# N32H49X register map
Vendor: Nsingtech Ltd.; File version: 1.0
Registers are 32-bit, read-write, reset 0x0 unless marked. A register's access mark holds for its fields unless they carry their own. Offsets are from the block's base; [hi:lo] are bit positions; {n}, {i} and the like mark numbered series; 'fields as' and 'values as' point back to an identical list.

## WWDG — window watchdog
Base 0x40000400
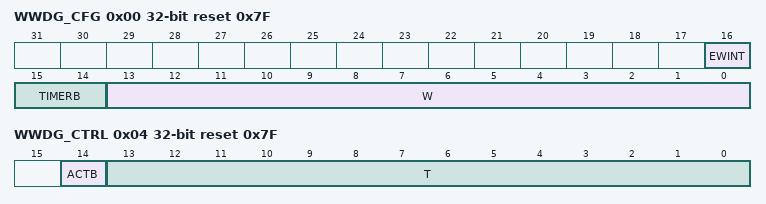
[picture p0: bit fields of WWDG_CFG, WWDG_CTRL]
0x00 WWDG_CFG reset 0x7F (reset mask 0x3FF)
  [16] EWINT, [15:14] TIMERB, [13:0] W
0x04 WWDG_CTRL reset 0x7F (reset mask 0xFF)
  [14] ACTB, [13:0] T
0x08 WWDG_STS
  [0] EWINTF

## DBG — debug support for MCU
Base 0xE0042000
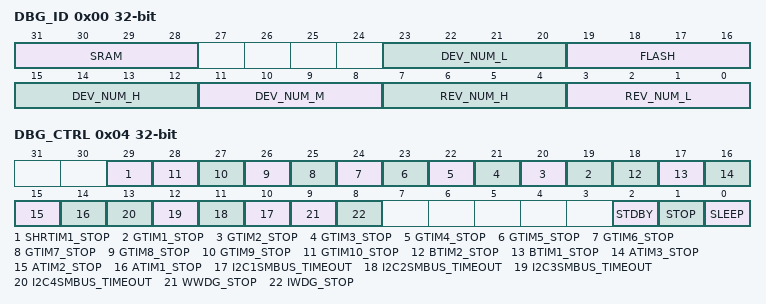
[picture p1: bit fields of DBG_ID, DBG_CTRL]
0x00 DBG_ID
  [31:28] SRAM, [23:20] DEV_NUM_L, [19:16] FLASH, [15:12] DEV_NUM_H, [11:8] DEV_NUM_M, [7:4] REV_NUM_H, [3:0] REV_NUM_L
0x04 DBG_CTRL (reset mask 0x3FFF07)
  [29] SHRTIM1_STOP, [n+18] GTIM{n}_STOP (n=1..10), [18] BTIM2_STOP, [17] BTIM1_STOP, [16] ATIM3_STOP, [15] ATIM2_STOP, [14] ATIM1_STOP, [n+9] I2C{n}SMBUS_TIMEOUT (n=1..4), [9] WWDG_STOP, [8] IWDG_STOP, [2] STDBY, [1] STOP, [0] SLEEP

## SPI1 — Serial peripheral interface
Base 0x40011800
Same registers: SPI2 0x40002400, SPI3 0x40002800, SPI4 0x40012C00, SPI5 0x40013000, SPI6 0x40013400
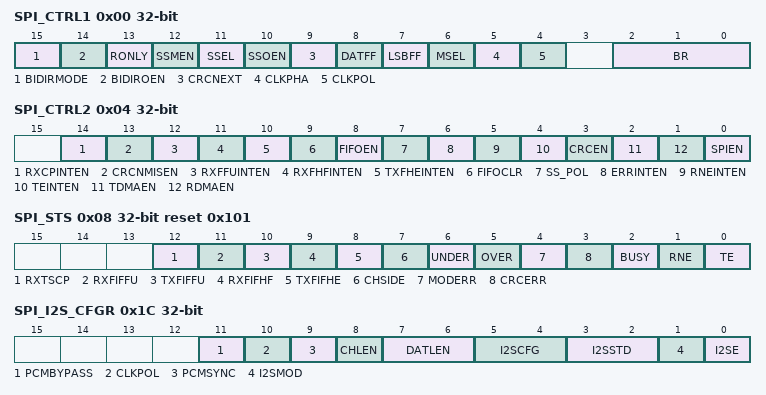
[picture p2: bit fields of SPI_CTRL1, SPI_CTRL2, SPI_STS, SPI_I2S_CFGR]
0x00 SPI_CTRL1
  [15] BIDIRMODE, [14] BIDIROEN, [13] RONLY, [12] SSMEN, [11] SSEL, [10] SSOEN, [9] CRCNEXT, [8] DATFF, [7] LSBFF, [6] MSEL, [5] CLKPHA, [4] CLKPOL, [2:0] BR
0x04 SPI_CTRL2
  [14] RXCPINTEN, [13] CRCNMISEN, [12] RXFFUINTEN, [11] RXFHFINTEN, [10] TXFHEINTEN, [9] FIFOCLR, [8] FIFOEN, [7] SS_POL, [6] ERRINTEN, [5] RNEINTEN, [4] TEINTEN, [3] CRCEN, [2] TDMAEN, [1] RDMAEN, [0] SPIEN
0x08 SPI_STS reset 0x101
  [12] RXTSCP, [11] RXFIFFU, [10] TXFIFFU, [9] RXFIFHF, [8] TXFIFHE, [7] CHSIDE, [6] UNDER, [5] OVER, [4] MODERR, [3] CRCERR, [2] BUSY, [1] RNE, [0] TE
0x0C SPI_DAT
  [15:0] DAT
0x10 SPI_CRCTDAT
  [15:0] CRCTDAT
0x14 SPI_CRCRDAT
  [15:0] CRCRDAT
0x18 SPI_CRCPOLY reset 0x7
  [15:0] CRCPOLY
0x1C SPI_I2S_CFGR
  [11] PCMBYPASS, [10] CLKPOL, [9] PCMSYNC, [8] CHLEN, [7:6] DATLEN, [5:4] I2SCFG, [3:2] I2SSTD, [1] I2SMOD, [0] I2SE
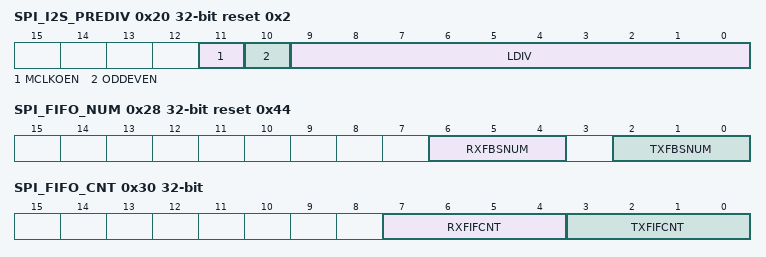
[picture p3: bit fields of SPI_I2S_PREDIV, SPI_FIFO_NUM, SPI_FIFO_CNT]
0x20 SPI_I2S_PREDIV reset 0x2
  [11] MCLKOEN, [10] ODDEVEN, [9:0] LDIV
0x24 SPI_RX_FIFO
  [15:0] RXFIFDAT
0x28 SPI_FIFO_NUM reset 0x44
  [6:4] RXFBSNUM, [2:0] TXFBSNUM
0x30 SPI_FIFO_CNT
  [7:4] RXFIFCNT, [3:0] TXFIFCNT
0x34 SPI_TRANS_NUM
  [15:0] TRANSNUM
0x38 SPI_CR3
  [3:0] DELAYTIME

## I2S2_EXT — Inter—IC Sound
Base 0x40002600
Same registers: I2S3_EXT 0x40002A00
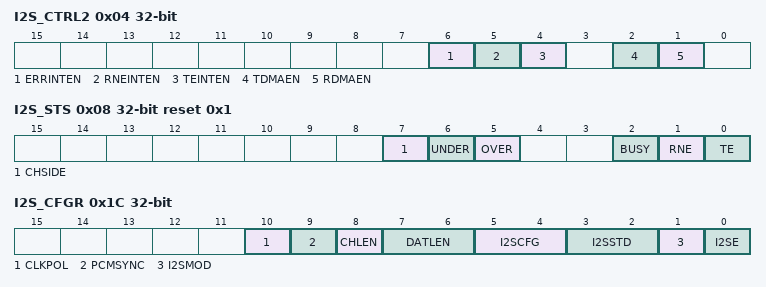
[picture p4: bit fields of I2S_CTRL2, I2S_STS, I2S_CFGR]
0x04 I2S_CTRL2
  [6] ERRINTEN, [5] RNEINTEN, [4] TEINTEN, [2] TDMAEN, [1] RDMAEN
0x08 I2S_STS reset 0x1
  [7] CHSIDE, [6] UNDER, [5] OVER, [2] BUSY, [1] RNE, [0] TE
0x0C I2S_DAT
  [15:0] DAT
0x1C I2S_CFGR
  [10] CLKPOL, [9] PCMSYNC, [8] CHLEN, [7:6] DATLEN, [5:4] I2SCFG, [3:2] I2SSTD, [1] I2SMOD, [0] I2SE

## DMA1 — Direct memory access controller
Base 0x40020000
Same registers: DMA2 0x40020400
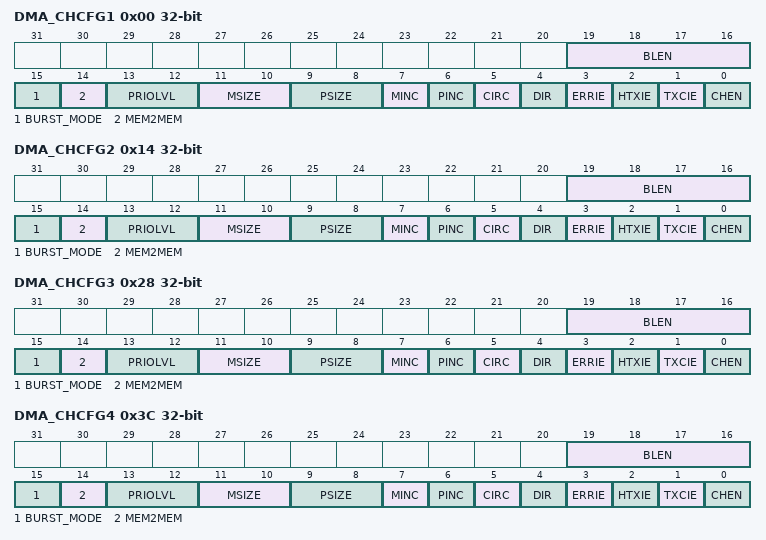
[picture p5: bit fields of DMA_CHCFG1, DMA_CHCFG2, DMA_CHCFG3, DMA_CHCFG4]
0x00 DMA_CHCFG1
  [19:16] BLEN, [15] BURST_MODE, [14] MEM2MEM, [13:12] PRIOLVL, [11:10] MSIZE, [9:8] PSIZE, [7] MINC, [6] PINC, [5] CIRC, [4] DIR, [3] ERRIE, [2] HTXIE, [1] TXCIE, [0] CHEN
0x04 DMA_MADDR1
  [31:0] ADDR
0x08 DMA_PADDR1
  [31:0] ADDR
0x0C DMA_CHSEL1
  [7:0] CH_SEL
0x10 DMA_TXNUM1
  [15:0] NDTX
0x14 DMA_CHCFG2
  fields as DMA_CHCFG1
0x18 DMA_MADDR2
  [31:0] ADDR
0x1C DMA_PADDR2
  [31:0] ADDR
0x20 DMA_CHSEL2
  [7:0] CH_SEL
0x24 DMA_TXNUM2
  [15:0] NDTX
0x28 DMA_CHCFG3
  fields as DMA_CHCFG1
0x2C DMA_MADDR3
  [31:0] ADDR
0x30 DMA_PADDR3
  [31:0] ADDR
0x34 DMA_CHSEL3
  [7:0] CH_SEL
0x38 DMA_TXNUM3
  [15:0] NDTX
0x3C DMA_CHCFG4
  fields as DMA_CHCFG1
0x40 DMA_MADDR4
  [31:0] ADDR
0x44 DMA_PADDR4
  [31:0] ADDR
0x48 DMA_CHSEL4
  [7:0] CH_SEL
0x4C DMA_TXNUM4
  [15:0] NDTX
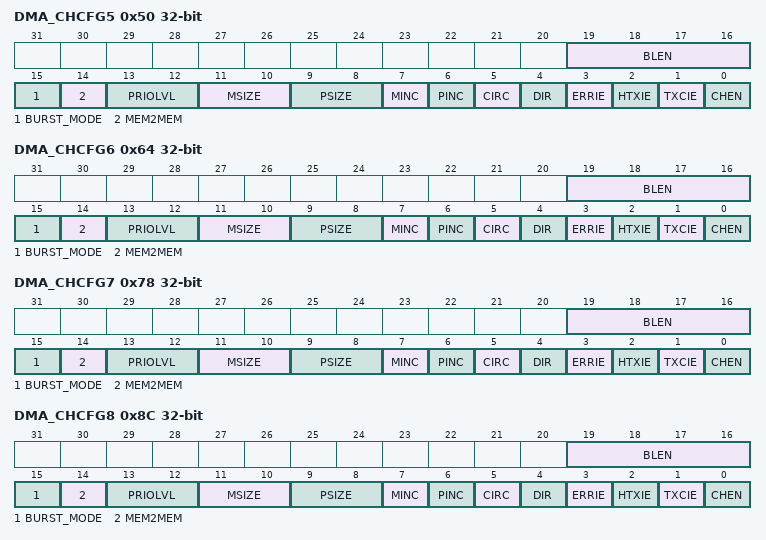
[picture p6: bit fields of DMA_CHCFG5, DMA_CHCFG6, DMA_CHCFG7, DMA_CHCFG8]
0x50 DMA_CHCFG5
  fields as DMA_CHCFG1
0x54 DMA_MADDR5
  [31:0] ADDR
0x58 DMA_PADDR5
  [31:0] ADDR
0x5C DMA_CHSEL5
  [7:0] CH_SEL
0x60 DMA_TXNUM5
  [15:0] NDTX
0x64 DMA_CHCFG6
  fields as DMA_CHCFG1
0x68 DMA_MADDR6
  [31:0] ADDR
0x6C DMA_PADDR6
  [31:0] ADDR
0x70 DMA_CHSEL6
  [7:0] CH_SEL
0x74 DMA_TXNUM6
  [15:0] NDTX
0x78 DMA_CHCFG7
  fields as DMA_CHCFG1
0x7C DMA_MADDR7
  [31:0] ADDR
0x80 DMA_PADDR7
  [31:0] ADDR
0x84 DMA_CHSEL7
  [7:0] CH_SEL
0x88 DMA_TXNUM7
  [15:0] NDTX
0x8C DMA_CHCFG8
  fields as DMA_CHCFG1
0x90 DMA_MADDR8
  [31:0] ADDR
0x94 DMA_PADDR8
  [31:0] ADDR
0x98 DMA_CHSEL8
  [7:0] CH_SEL
0x9C DMA_TXNUM8
  [15:0] NDTX
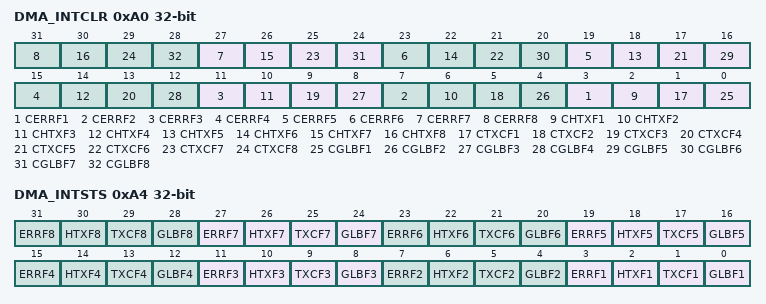
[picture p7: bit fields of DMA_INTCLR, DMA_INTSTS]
0xA0 DMA_INTCLR
  [4n-1] CERRF{n} (n=1..8), [4n-2] CHTXF{n} (n=1..8), [4n-3] CTXCF{n} (n=1..8), [4n-4] CGLBF{n} (n=1..8)
0xA4 DMA_INTSTS ro
  [4n-1] ERRF{n} (n=1..8), [4n-2] HTXF{n} (n=1..8), [4n-3] TXCF{n} (n=1..8), [4n-4] GLBF{n} (n=1..8)
0xA8 DMA_BURSTEN reset 0x1
  [0] BURST_BYPASS
